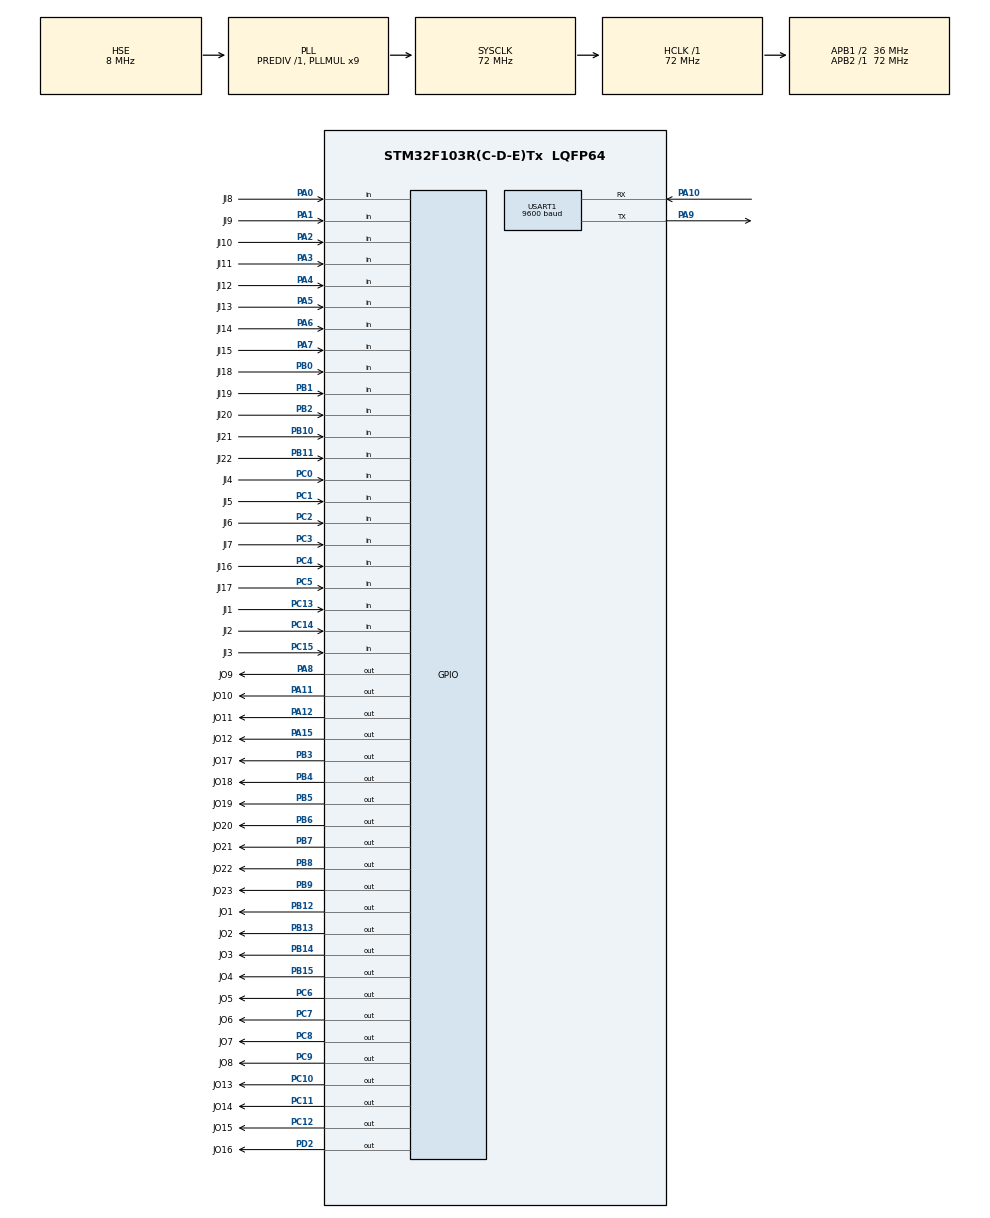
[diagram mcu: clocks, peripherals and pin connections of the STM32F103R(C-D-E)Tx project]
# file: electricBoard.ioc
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Mcu.Family=STM32F1
Mcu.Name=STM32F103R(C-D-E)Tx
Mcu.Package=LQFP64
NVIC.PriorityGroup=NVIC_PRIORITYGROUP_4
PA0-WKUP.GPIO_Label=JI8
PA0-WKUP.GPIO_PuPd=GPIO_PULLUP
PA0-WKUP.Signal=GPIO_Input
PA1.GPIO_Label=JI9
PA1.GPIO_PuPd=GPIO_PULLUP
PA1.Signal=GPIO_Input
PA10.Mode=Asynchronous
PA10.Signal=USART1_RX
PA11.GPIO_Label=JO10
PA11.Signal=GPIO_Output
PA12.GPIO_Label=JO11
PA12.Signal=GPIO_Output
PA13.Mode=Serial_Wire
PA13.Signal=SYS_JTMS-SWDIO
PA14.Mode=Serial_Wire
PA14.Signal=SYS_JTCK-SWCLK
PA15.GPIO_Label=JO12
PA15.Signal=GPIO_Output
PA2.GPIO_Label=JI10
PA2.GPIO_PuPd=GPIO_PULLUP
PA2.Signal=GPIO_Input
PA3.GPIO_Label=JI11
PA3.GPIO_PuPd=GPIO_PULLUP
PA3.Signal=GPIO_Input
PA4.GPIO_Label=JI12
PA4.GPIO_PuPd=GPIO_PULLUP
PA4.Signal=GPIO_Input
PA5.GPIO_Label=JI13
PA5.GPIO_PuPd=GPIO_PULLUP
PA5.Signal=GPIO_Input
PA6.GPIO_Label=JI14
PA6.GPIO_PuPd=GPIO_PULLUP
PA6.Signal=GPIO_Input
PA7.GPIO_Label=JI15
PA7.GPIO_PuPd=GPIO_PULLUP
PA7.Signal=GPIO_Input
PA8.GPIO_Label=JO9
PA8.Signal=GPIO_Output
PA9.Mode=Asynchronous
PA9.Signal=USART1_TX
PB0.GPIO_Label=JI18
PB0.GPIO_PuPd=GPIO_PULLUP
PB0.Signal=GPIO_Input
PB1.GPIO_Label=JI19
PB1.GPIO_PuPd=GPIO_PULLUP
PB1.Signal=GPIO_Input
PB10.GPIO_Label=JI21
PB10.GPIO_PuPd=GPIO_PULLUP
PB10.Signal=GPIO_Input
PB11.GPIO_Label=JI22
PB11.GPIO_PuPd=GPIO_PULLUP
PB11.Signal=GPIO_Input
PB12.GPIO_Label=JO1
PB12.Signal=GPIO_Output
PB13.GPIO_Label=JO2
PB13.Signal=GPIO_Output
PB14.GPIO_Label=JO3
PB14.Signal=GPIO_Output
PB15.GPIO_Label=JO4
PB15.Signal=GPIO_Output
PB2.GPIO_Label=JI20
PB2.GPIO_PuPd=GPIO_PULLUP
PB2.Signal=GPIO_Input
PB3.GPIO_Label=JO17
PB3.Signal=GPIO_Output
PB4.GPIO_Label=JO18
PB4.Signal=GPIO_Output
PB5.GPIO_Label=JO19
PB5.Signal=GPIO_Output
PB6.GPIO_Label=JO20
PB6.Signal=GPIO_Output
PB7.GPIO_Label=JO21
PB7.Signal=GPIO_Output
PB8.GPIO_Label=JO22
PB8.Signal=GPIO_Output
PB9.GPIO_Label=JO23
PB9.Signal=GPIO_Output
PC0.GPIO_Label=JI4
PC0.GPIO_PuPd=GPIO_PULLUP
PC0.Signal=GPIO_Input
PC1.GPIO_Label=JI5
PC1.GPIO_PuPd=GPIO_PULLUP
PC1.Signal=GPIO_Input
PC10.GPIO_Label=JO13
PC10.Signal=GPIO_Output
PC11.GPIO_Label=JO14
PC11.Signal=GPIO_Output
PC12.GPIO_Label=JO15
PC12.Signal=GPIO_Output
PC13-TAMPER-RTC.GPIO_Label=JI1
PC13-TAMPER-RTC.GPIO_PuPd=GPIO_PULLUP
PC13-TAMPER-RTC.Signal=GPIO_Input
PC14-OSC32_IN.GPIO_Label=JI2
PC14-OSC32_IN.GPIO_PuPd=GPIO_PULLUP
PC14-OSC32_IN.Signal=GPIO_Input
PC15-OSC32_OUT.GPIO_Label=JI3
PC15-OSC32_OUT.GPIO_PuPd=GPIO_PULLUP
PC15-OSC32_OUT.Signal=GPIO_Input
PC2.GPIO_Label=JI6
PC2.GPIO_PuPd=GPIO_PULLUP
PC2.Signal=GPIO_Input
PC3.GPIO_Label=JI7
PC3.GPIO_PuPd=GPIO_PULLUP
PC3.Signal=GPIO_Input
PC4.GPIO_Label=JI16
PC4.GPIO_PuPd=GPIO_PULLUP
PC4.Signal=GPIO_Input
PC5.GPIO_Label=JI17
PC5.GPIO_PuPd=GPIO_PULLUP
PC5.Signal=GPIO_Input
PC6.GPIO_Label=JO5
PC6.Signal=GPIO_Output
PC7.GPIO_Label=JO6
PC7.Signal=GPIO_Output
PC8.GPIO_Label=JO7
PC8.Signal=GPIO_Output
PC9.GPIO_Label=JO8
PC9.Signal=GPIO_Output
PD0-OSC_IN.Mode=HSE-External-Oscillator
PD0-OSC_IN.Signal=RCC_OSC_IN
PD1-OSC_OUT.Mode=HSE-External-Oscillator
PD1-OSC_OUT.Signal=RCC_OSC_OUT
PD2.GPIO_Label=JO16
PD2.Signal=GPIO_Output
ProjectManager.HeapSize=0x200
ProjectManager.StackSize=0x400
ProjectManager.TargetToolchain=STM32CubeIDE
RCC.AHBFreq_Value=72000000
RCC.APB1CLKDivider=RCC_HCLK_DIV2
RCC.APB1Freq_Value=36000000
RCC.APB1TimFreq_Value=72000000
RCC.APB2Freq_Value=72000000
RCC.APB2TimFreq_Value=72000000
RCC.HCLKFreq_Value=72000000
RCC.PLLMUL=RCC_PLL_MUL9
RCC.PLLSourceVirtual=RCC_PLLSOURCE_HSE
RCC.SYSCLKFreq_VALUE=72000000
RCC.SYSCLKSource=RCC_SYSCLKSOURCE_PLLCLK
RCC.USBFreq_Value=72000000
USART1.BaudRate=9600
USART1.VirtualMode=VM_ASYNC
board=custom

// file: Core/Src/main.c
/* USER CODE BEGIN Header */
/**
  ******************************************************************************
  * @file           : main.c
  * @brief          : Main program body
  ******************************************************************************
  * @attention
  *
  * <h2><center>&copy; Copyright (c) 2020 STMicroelectronics.
  * All rights reserved.</center></h2>
  *
  * This software component is licensed by ST under BSD 3-Clause license,
  * the "License"; You may not use this file except in compliance with the
  * License. You may obtain a copy of the License at:
  *                        opensource.org/licenses/BSD-3-Clause
  *
  ******************************************************************************
  */
/* USER CODE END Header */
#include "main.h"

UART_HandleTypeDef huart1;

void SystemClock_Config(void);
static void MX_GPIO_Init(void);
static void MX_USART1_UART_Init(void);

/* USER CODE BEGIN 0 */

//printf重定�?
PUTCHAR_PROTOTYPE
{
    //具体哪个串口可以更改huart1为其它串�?
    HAL_UART_Transmit(&huart1, (uint8_t *)&ch, 1 , 2);
    return ch;
}

/* USER CODE END 0 */

int main(void)
{

  /* MCU Configuration--------------------------------------------------------*/

  /* Reset of all peripherals, Initializes the Flash interface and the Systick. */
  HAL_Init();

  /* Configure the system clock */
  SystemClock_Config();

  /* Initialize all configured peripherals */
  MX_GPIO_Init();
  MX_USART1_UART_Init();

  /* Infinite loop */
  /* USER CODE BEGIN WHILE */
  while (1)
  {
	  int a = 0x01;
	  user_main_printf("rest");
	  printf("%x",a);
	  HAL_Delay(1000);
	  JO16RESET;
	  HAL_Delay(1000);
	  JO16SET;
    /* USER CODE END WHILE */

  }
}

void SystemClock_Config(void)
{
  RCC_OscInitTypeDef RCC_OscInitStruct = {0};
  RCC_ClkInitTypeDef RCC_ClkInitStruct = {0};

  /** Initializes the RCC Oscillators according to the specified parameters
  * in the RCC_OscInitTypeDef structure.
  */
  RCC_OscInitStruct.OscillatorType = RCC_OSCILLATORTYPE_HSE;
  RCC_OscInitStruct.HSEState = RCC_HSE_ON;
  RCC_OscInitStruct.HSEPredivValue = RCC_HSE_PREDIV_DIV1;
  RCC_OscInitStruct.HSIState = RCC_HSI_ON;
  RCC_OscInitStruct.PLL.PLLState = RCC_PLL_ON;
  RCC_OscInitStruct.PLL.PLLSource = RCC_PLLSOURCE_HSE;
  RCC_OscInitStruct.PLL.PLLMUL = RCC_PLL_MUL9;
  if (HAL_RCC_OscConfig(&RCC_OscInitStruct) != HAL_OK)
  {
    Error_Handler();
  }
  /** Initializes the CPU, AHB and APB buses clocks
  */
  RCC_ClkInitStruct.ClockType = RCC_CLOCKTYPE_HCLK|RCC_CLOCKTYPE_SYSCLK
                              |RCC_CLOCKTYPE_PCLK1|RCC_CLOCKTYPE_PCLK2;
  RCC_ClkInitStruct.SYSCLKSource = RCC_SYSCLKSOURCE_PLLCLK;
  RCC_ClkInitStruct.AHBCLKDivider = RCC_SYSCLK_DIV1;
  RCC_ClkInitStruct.APB1CLKDivider = RCC_HCLK_DIV2;
  RCC_ClkInitStruct.APB2CLKDivider = RCC_HCLK_DIV1;

  if (HAL_RCC_ClockConfig(&RCC_ClkInitStruct, FLASH_LATENCY_2) != HAL_OK)
  {
    Error_Handler();
  }
}

static void MX_USART1_UART_Init(void)
{

  huart1.Instance = USART1;
  huart1.Init.BaudRate = 9600;
  huart1.Init.WordLength = UART_WORDLENGTH_8B;
  huart1.Init.StopBits = UART_STOPBITS_1;
  huart1.Init.Parity = UART_PARITY_NONE;
  huart1.Init.Mode = UART_MODE_TX_RX;
  huart1.Init.HwFlowCtl = UART_HWCONTROL_NONE;
  huart1.Init.OverSampling = UART_OVERSAMPLING_16;
  if (HAL_UART_Init(&huart1) != HAL_OK)
  {
    Error_Handler();
  }

}

static void MX_GPIO_Init(void)
{
  GPIO_InitTypeDef GPIO_InitStruct = {0};

  /* GPIO Ports Clock Enable */
  __HAL_RCC_GPIOC_CLK_ENABLE();
  __HAL_RCC_GPIOD_CLK_ENABLE();
  __HAL_RCC_GPIOA_CLK_ENABLE();
  __HAL_RCC_GPIOB_CLK_ENABLE();

  /*Configure GPIO pin Output Level */
  HAL_GPIO_WritePin(GPIOB, JO1_Pin|JO2_Pin|JO3_Pin|JO4_Pin
                          |JO17_Pin|JO18_Pin|JO19_Pin|JO20_Pin
                          |JO21_Pin|JO22_Pin|JO23_Pin, GPIO_PIN_RESET);

  /*Configure GPIO pin Output Level */
  HAL_GPIO_WritePin(GPIOC, JO5_Pin|JO6_Pin|JO7_Pin|JO8_Pin
                          |JO13_Pin|JO14_Pin|JO15_Pin, GPIO_PIN_RESET);

  /*Configure GPIO pin Output Level */
  HAL_GPIO_WritePin(GPIOA, JO9_Pin|JO10_Pin|JO11_Pin|JO12_Pin, GPIO_PIN_RESET);

  /*Configure GPIO pin Output Level */
  HAL_GPIO_WritePin(JO16_GPIO_Port, JO16_Pin, GPIO_PIN_RESET);

  /*Configure GPIO pins : JI1_Pin JI2_Pin JI3_Pin JI4_Pin
                           JI5_Pin JI6_Pin JI7_Pin JI16_Pin
                           JI17_Pin */
  GPIO_InitStruct.Pin = JI1_Pin|JI2_Pin|JI3_Pin|JI4_Pin
                          |JI5_Pin|JI6_Pin|JI7_Pin|JI16_Pin
                          |JI17_Pin;
  GPIO_InitStruct.Mode = GPIO_MODE_INPUT;
  GPIO_InitStruct.Pull = GPIO_PULLUP;
  HAL_GPIO_Init(GPIOC, &GPIO_InitStruct);

  /*Configure GPIO pins : JI8_Pin JI9_Pin JI10_Pin JI11_Pin
                           JI12_Pin JI13_Pin JI14_Pin JI15_Pin */
  GPIO_InitStruct.Pin = JI8_Pin|JI9_Pin|JI10_Pin|JI11_Pin
                          |JI12_Pin|JI13_Pin|JI14_Pin|JI15_Pin;
  GPIO_InitStruct.Mode = GPIO_MODE_INPUT;
  GPIO_InitStruct.Pull = GPIO_PULLUP;
  HAL_GPIO_Init(GPIOA, &GPIO_InitStruct);

  /*Configure GPIO pins : JI18_Pin JI19_Pin JI20_Pin JI21_Pin
                           JI22_Pin */
  GPIO_InitStruct.Pin = JI18_Pin|JI19_Pin|JI20_Pin|JI21_Pin
                          |JI22_Pin;
  GPIO_InitStruct.Mode = GPIO_MODE_INPUT;
  GPIO_InitStruct.Pull = GPIO_PULLUP;
  HAL_GPIO_Init(GPIOB, &GPIO_InitStruct);

  /*Configure GPIO pins : JO1_Pin JO2_Pin JO3_Pin JO4_Pin
                           JO17_Pin JO18_Pin JO19_Pin JO20_Pin
                           JO21_Pin JO22_Pin JO23_Pin */
  GPIO_InitStruct.Pin = JO1_Pin|JO2_Pin|JO3_Pin|JO4_Pin
                          |JO17_Pin|JO18_Pin|JO19_Pin|JO20_Pin
                          |JO21_Pin|JO22_Pin|JO23_Pin;
  GPIO_InitStruct.Mode = GPIO_MODE_OUTPUT_PP;
  GPIO_InitStruct.Pull = GPIO_NOPULL;
  GPIO_InitStruct.Speed = GPIO_SPEED_FREQ_LOW;
  HAL_GPIO_Init(GPIOB, &GPIO_InitStruct);

  /*Configure GPIO pins : JO5_Pin JO6_Pin JO7_Pin JO8_Pin
                           JO13_Pin JO14_Pin JO15_Pin */
  GPIO_InitStruct.Pin = JO5_Pin|JO6_Pin|JO7_Pin|JO8_Pin
                          |JO13_Pin|JO14_Pin|JO15_Pin;
  GPIO_InitStruct.Mode = GPIO_MODE_OUTPUT_PP;
  GPIO_InitStruct.Pull = GPIO_NOPULL;
  GPIO_InitStruct.Speed = GPIO_SPEED_FREQ_LOW;
  HAL_GPIO_Init(GPIOC, &GPIO_InitStruct);

  /*Configure GPIO pins : JO9_Pin JO10_Pin JO11_Pin JO12_Pin */
  GPIO_InitStruct.Pin = JO9_Pin|JO10_Pin|JO11_Pin|JO12_Pin;
  GPIO_InitStruct.Mode = GPIO_MODE_OUTPUT_PP;
  GPIO_InitStruct.Pull = GPIO_NOPULL;
  GPIO_InitStruct.Speed = GPIO_SPEED_FREQ_LOW;
  HAL_GPIO_Init(GPIOA, &GPIO_InitStruct);

  /*Configure GPIO pin : JO16_Pin */
  GPIO_InitStruct.Pin = JO16_Pin;
  GPIO_InitStruct.Mode = GPIO_MODE_OUTPUT_PP;
  GPIO_InitStruct.Pull = GPIO_NOPULL;
  GPIO_InitStruct.Speed = GPIO_SPEED_FREQ_LOW;
  HAL_GPIO_Init(JO16_GPIO_Port, &GPIO_InitStruct);

}

void Error_Handler(void)
{
  __disable_irq();
  while (1)
  {
  }
}

/************************ (C) COPYRIGHT STMicroelectronics *****END OF FILE****/
